VERSION ""

NS_ :

BS_:

BU_: FlexSense

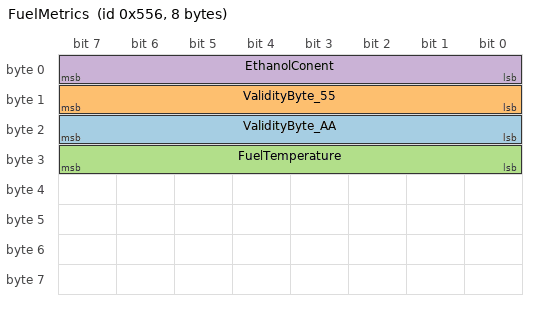
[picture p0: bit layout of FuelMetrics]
BO_ 1366 FuelMetrics: 8 FlexSense
 SG_ ValidityByte_AA : 23|8@0+ (1,0) [0|255] "" Vector__XXX
 SG_ ValidityByte_55 : 15|8@0+ (1,0) [0|255] "" Vector__XXX
 SG_ FuelTemperature : 31|8@0+ (1,40) [40|295] "degC" Vector__XXX
 SG_ EthanolConent : 7|8@0+ (1,0) [0|255] "%" Vector__XXX

CM_ SG_ 1366 ValidityByte_AA "This byte must always read 0xAA";
CM_ SG_ 1366 ValidityByte_55 "This byte must always read 0x55";
BA_DEF_ BO_  "TxRate" INT 10 10000;
BA_DEF_  "BusType" STRING ;
BA_DEF_DEF_  "TxRate" 1000;
BA_DEF_DEF_  "BusType" "CAN";
BA_ "TxRate" BO_ 1366 500;
